# F28x7x_output_xbar_regs register map
Vendor: Texas Instruments
Peripheral module from a debugger description file (folder C2000).
Address unit: 16 bits
Registers are 32-bit, read-write, no defined reset value unless marked. A register's access mark holds for its fields unless they carry their own. Offsets are as the file gives them; lines under a group give offsets from that group; [hi:lo] are bit positions; {n}, {i} and the like mark numbered series; 'fields as' and 'values as' point back to an identical list; <NAME> marks a mode.

## OUTPUT_XBAR_REGS — OUTPUT XBAR Registers
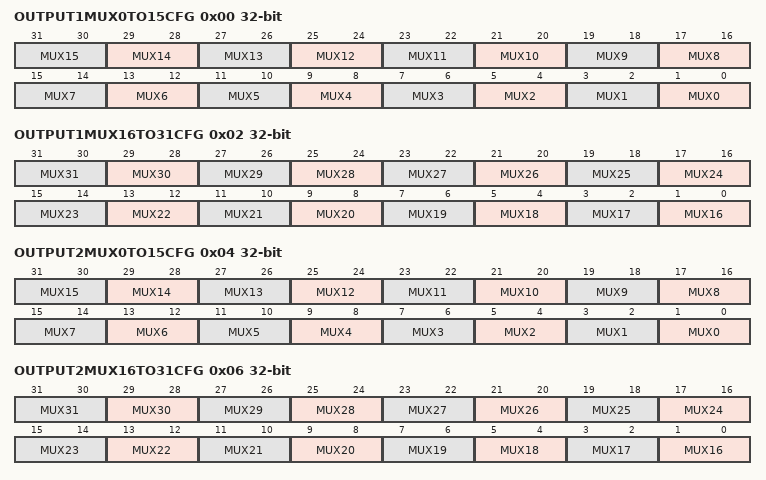
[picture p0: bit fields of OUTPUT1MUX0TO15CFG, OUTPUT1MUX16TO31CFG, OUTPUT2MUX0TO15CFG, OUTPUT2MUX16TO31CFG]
0x00 OUTPUT1MUX0TO15CFG — Output X-BAR Mux Configuration for Output 1
  [2n+1:2n] MUX{n} (n=0..15) — Mux{n} Configuration for OUTPUT1 of OUTPUT-XBAR
0x02 OUTPUT1MUX16TO31CFG — Output X-BAR Mux Configuration for Output 1
  [2n-31:2n-32] MUX{n} (n=16..31) — Mux{n} Configuration for OUTPUT1 of OUTPUT-XBAR
0x04 OUTPUT2MUX0TO15CFG — Output X-BAR Mux Configuration for Output 2
  [2n+1:2n] MUX{n} (n=0..15) — Mux{n} Configuration for OUTPUT2 of OUTPUT-XBAR
0x06 OUTPUT2MUX16TO31CFG — Output X-BAR Mux Configuration for Output 2
  [2n-31:2n-32] MUX{n} (n=16..31) — Mux{n} Configuration for OUTPUT2 of OUTPUT-XBAR
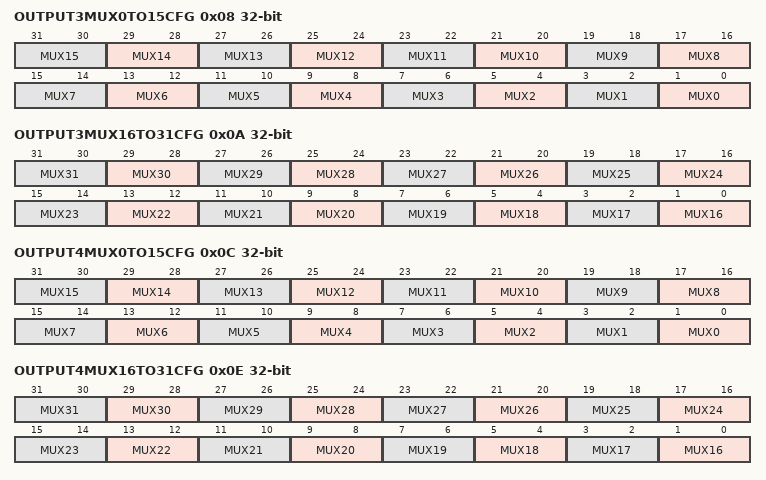
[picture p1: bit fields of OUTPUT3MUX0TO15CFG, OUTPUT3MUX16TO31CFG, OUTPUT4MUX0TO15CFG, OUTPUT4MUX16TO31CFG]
0x08 OUTPUT3MUX0TO15CFG — Output X-BAR Mux Configuration for Output 3
  [2n+1:2n] MUX{n} (n=0..15) — Mux{n} Configuration for OUTPUT3 of OUTPUT-XBAR
0x0A OUTPUT3MUX16TO31CFG — Output X-BAR Mux Configuration for Output 3
  [2n-31:2n-32] MUX{n} (n=16..31) — Mux{n} Configuration for OUTPUT3 of OUTPUT-XBAR
0x0C OUTPUT4MUX0TO15CFG — Output X-BAR Mux Configuration for Output 4
  [2n+1:2n] MUX{n} (n=0..15) — Mux{n} Configuration for OUTPUT4 of OUTPUT-XBAR
0x0E OUTPUT4MUX16TO31CFG — Output X-BAR Mux Configuration for Output 4
  [2n-31:2n-32] MUX{n} (n=16..31) — Mux{n} Configuration for OUTPUT4 of OUTPUT-XBAR
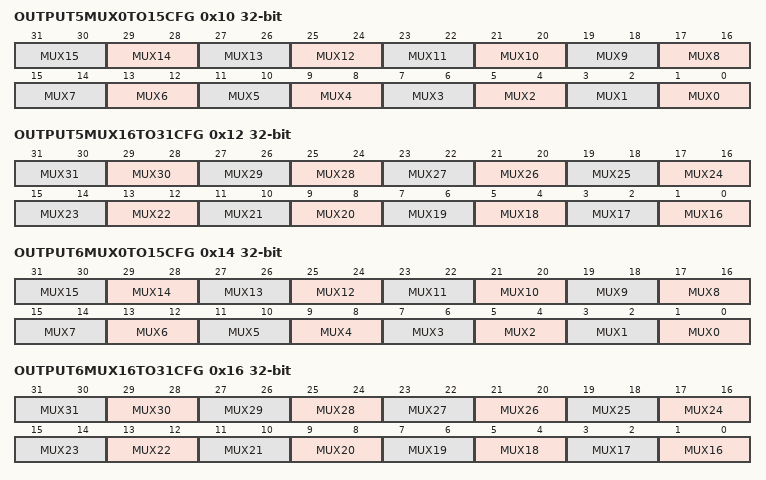
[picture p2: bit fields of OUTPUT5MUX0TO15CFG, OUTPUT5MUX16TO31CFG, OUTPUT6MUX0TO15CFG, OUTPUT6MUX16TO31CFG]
0x10 OUTPUT5MUX0TO15CFG — Output X-BAR Mux Configuration for Output 5
  [2n+1:2n] MUX{n} (n=0..15) — Mux{n} Configuration for OUTPUT5 of OUTPUT-XBAR
0x12 OUTPUT5MUX16TO31CFG — Output X-BAR Mux Configuration for Output 5
  [2n-31:2n-32] MUX{n} (n=16..31) — Mux{n} Configuration for OUTPUT5 of OUTPUT-XBAR
0x14 OUTPUT6MUX0TO15CFG — Output X-BAR Mux Configuration for Output 6
  [2n+1:2n] MUX{n} (n=0..15) — Mux{n} Configuration for OUTPUT6 of OUTPUT-XBAR
0x16 OUTPUT6MUX16TO31CFG — Output X-BAR Mux Configuration for Output 6
  [2n-31:2n-32] MUX{n} (n=16..31) — Mux{n} Configuration for OUTPUT6 of OUTPUT-XBAR
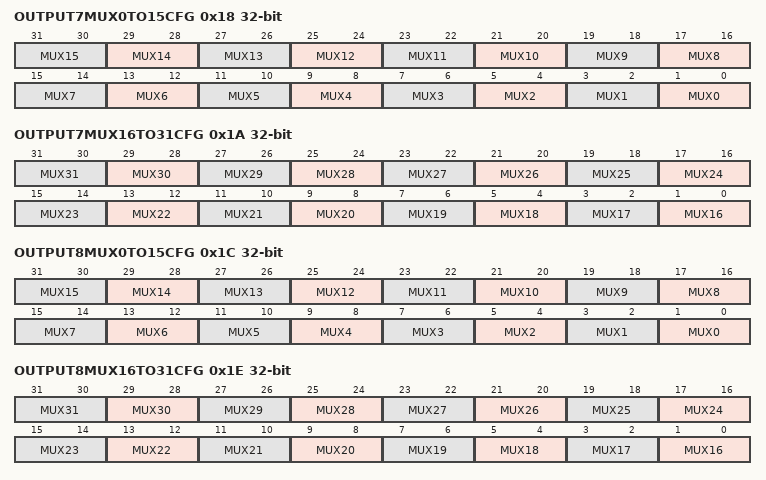
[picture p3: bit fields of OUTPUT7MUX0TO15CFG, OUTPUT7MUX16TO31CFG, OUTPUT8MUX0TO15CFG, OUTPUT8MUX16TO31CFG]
0x18 OUTPUT7MUX0TO15CFG — Output X-BAR Mux Configuration for Output 7
  [2n+1:2n] MUX{n} (n=0..15) — Mux{n} Configuration for OUTPUT7 of OUTPUT-XBAR
0x1A OUTPUT7MUX16TO31CFG — Output X-BAR Mux Configuration for Output 7
  [2n-31:2n-32] MUX{n} (n=16..31) — Mux{n} Configuration for OUTPUT7 of OUTPUT-XBAR
0x1C OUTPUT8MUX0TO15CFG — Output X-BAR Mux Configuration for Output 8
  [2n+1:2n] MUX{n} (n=0..15) — Mux{n} Configuration for OUTPUT8 of OUTPUT-XBAR
0x1E OUTPUT8MUX16TO31CFG — Output X-BAR Mux Configuration for Output 8
  [2n-31:2n-32] MUX{n} (n=16..31) — Mux{n} Configuration for OUTPUT8 of OUTPUT-XBAR
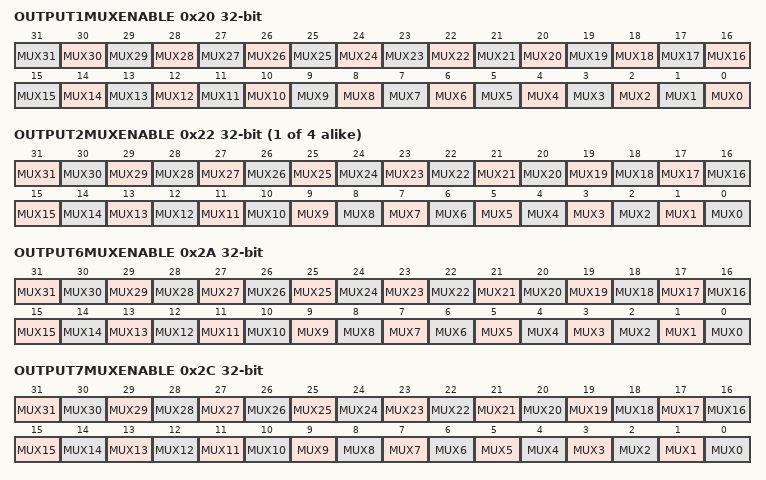
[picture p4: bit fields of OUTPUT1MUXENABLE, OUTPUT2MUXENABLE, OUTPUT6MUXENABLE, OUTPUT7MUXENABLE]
0x20 OUTPUT1MUXENABLE — Output X-BAR Mux Enable for Output 1
  [n] MUX{n} (n=0..31) — Mux{n} to drive OUTPUT1 of OUTPUT-XBAR
{0x1E+2i} OUTPUT{i}MUXENABLE (i=2..5) — Output X-BAR Mux Enable for Output {i}
  [n] MUX{n} (n=1..31) — Mux{n} to drive OUTPUT{i} of OUTPUT-XBAR
  [0] MUX0 — mux0 to drive OUTPUT{i} of OUTPUT-XBAR
0x2A OUTPUT6MUXENABLE — Output X-BAR Mux Enable for Output 6
  [n] MUX{n} (n=17..31) — Mux{n} to drive OUTPUT6 of OUTPUT-XBAR
  [16] MUX16 — Mux16 to OUTPUT6 of OUTPUT-XBAR
  [n] MUX{n} (n=1..15) — Mux{n} to drive OUTPUT6 of OUTPUT-XBAR
  [0] MUX0 — mux0 to drive OUTPUT6 of OUTPUT-XBAR
0x2C OUTPUT7MUXENABLE — Output X-BAR Mux Enable for Output 7
  [n] MUX{n} (n=1..31) — Mux{n} to drive OUTPUT7 of OUTPUT-XBAR
  [0] MUX0 — mux0 to drive OUTPUT7 of OUTPUT-XBAR
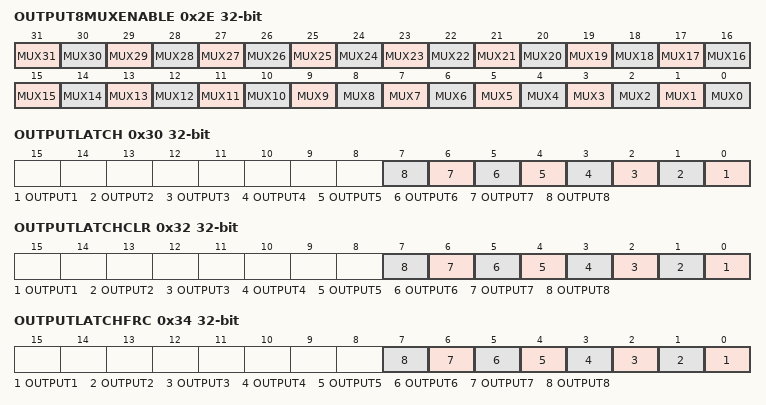
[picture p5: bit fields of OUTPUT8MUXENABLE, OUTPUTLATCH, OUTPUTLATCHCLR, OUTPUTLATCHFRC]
0x2E OUTPUT8MUXENABLE — Output X-BAR Mux Enable for Output 8
  [n] MUX{n} (n=1..31) — Mux{n} to drive OUTPUT8 of OUTPUT-XBAR
  [0] MUX0 — mux0 to drive OUTPUT8 of OUTPUT-XBAR
0x30 OUTPUTLATCH ro — Output X-BAR Output Latch
  [n-1] OUTPUT{n} (n=1..8) — Records the OUTPUT{n} of OUTPUT-XBAR
0x32 OUTPUTLATCHCLR access not given — Output X-BAR Output Latch Clear
  [n-1] OUTPUT{n} (n=1..8) — Clears the Output-Latch for OUTPUT{n} of OUTPUT-XBAR (access R=0/W=1)
0x34 OUTPUTLATCHFRC access not given — Output X-BAR Output Latch Clear
  [n-1] OUTPUT{n} (n=1..8) — Sets the Output-Latch for OUTPUT{n} of OUTPUT-XBAR (access R=0/W=1)
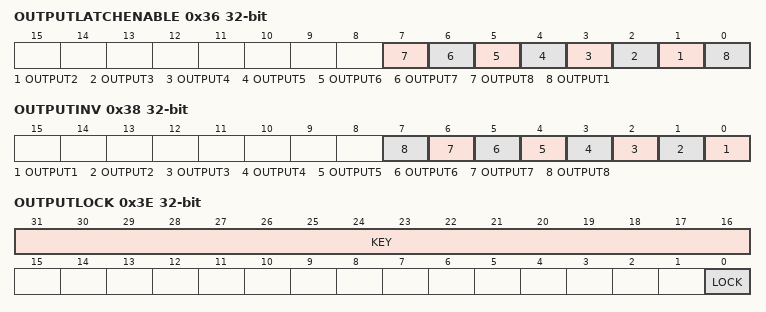
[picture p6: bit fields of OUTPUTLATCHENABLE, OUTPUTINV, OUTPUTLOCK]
0x36 OUTPUTLATCHENABLE — Output X-BAR Output Latch Enable
  [n-1] OUTPUT{n} (n=2..8) — Selects the output latch to drive output{n-1} for OUTPUT-XBAR
  [0] OUTPUT1 — Selects the output latch to drive OUTPUT1 for OUTPUT-XBAR
0x38 OUTPUTINV — Output X-BAR Output Inversion
  [n-1] OUTPUT{n} (n=1..8) — Selects polarity for OUTPUT{n} of OUTPUT-XBAR
0x3E OUTPUTLOCK access not given — Output X-BAR Configuration Lock register
  [31:16] KEY — Write Protection KEY (access R=0/W=1)
  [0] LOCK — Locks the configuration for OUTPUT-XBAR (access R/SOnce)
